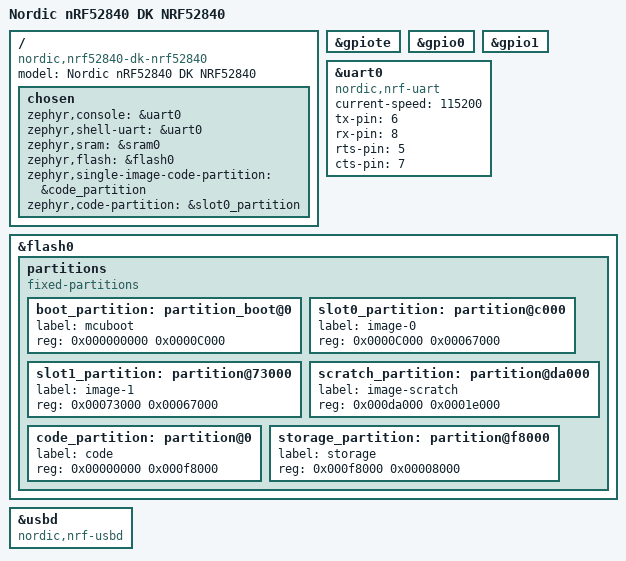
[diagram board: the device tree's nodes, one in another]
/*
 * Copyright (c) 2017 Linaro Limited
 *
 * SPDX-License-Identifier: Apache-2.0
 */

/dts-v1/;
#include <nordic/nrf52840_qiaa.dtsi>

/ {
	model = "Nordic nRF52840 DK NRF52840";
	compatible = "nordic,nrf52840-dk-nrf52840";

	chosen {
		zephyr,console = &uart0;
		zephyr,shell-uart = &uart0;
		zephyr,sram = &sram0;
		zephyr,flash = &flash0;
		zephyr,single-image-code-partition = &code_partition;
		zephyr,code-partition = &slot0_partition;
	};
};

&gpiote {
	status = "okay";
};

&gpio0 {
	status = "okay";
};

&gpio1 {
	status = "okay";
};

&uart0 {
	compatible = "nordic,nrf-uart";
	current-speed = <115200>;
	status = "okay";
	tx-pin = <6>;
	rx-pin = <8>;
	rts-pin = <5>;
	cts-pin = <7>;
};

&flash0 {

	/* Default flash partitioning.
	 *
	 * Note: A Zephyr build should use partitions belonging
	 * to the same flash layout.
	 */
	partitions {
		compatible = "fixed-partitions";
		#address-cells = <1>;
		#size-cells = <1>;

	/* Flash layout with MCUboot */
		boot_partition: partition_boot@0 {
			label = "mcuboot";
			reg = <0x000000000 0x0000C000>;
		};
		slot0_partition: partition@c000 {
			label = "image-0";
			reg = <0x0000C000 0x00067000>;
		};
		slot1_partition: partition@73000 {
			label = "image-1";
			reg = <0x00073000 0x00067000>;
		};
		scratch_partition: partition@da000 {
			label = "image-scratch";
			reg = <0x000da000 0x0001e000>;
		};

	/* Flash layout without MCUboot */
		code_partition: partition@0 {
			label = "code";
			reg = <0x00000000 0x000f8000>;
		};

	/* Common to both layouts */
		storage_partition: partition@f8000 {
			label = "storage";
			reg = <0x000f8000 0x00008000>;
		};
	};
};

&usbd {
	compatible = "nordic,nrf-usbd";
	status = "okay";
};
